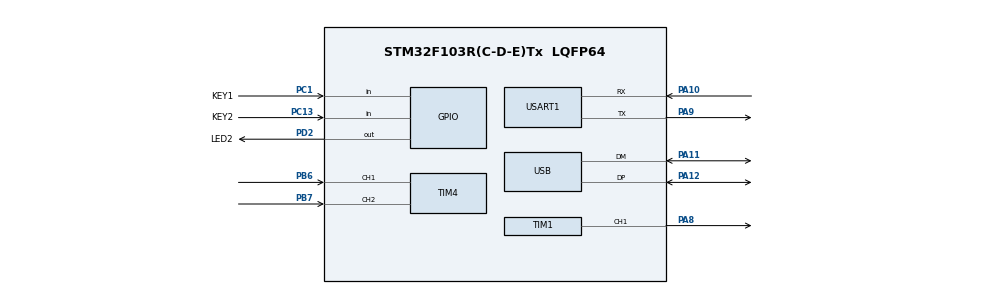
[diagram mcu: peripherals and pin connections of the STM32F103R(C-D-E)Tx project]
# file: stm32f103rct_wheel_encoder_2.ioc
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Mcu.Family=STM32F1
Mcu.Name=STM32F103R(C-D-E)Tx
Mcu.Package=LQFP64
NVIC.PriorityGroup=NVIC_PRIORITYGROUP_4
NVIC.TIM4_IRQn=true\:0\:0\:false\:false\:true\:true\:true\:true
NVIC.USART1_IRQn=true\:0\:0\:false\:false\:true\:true\:true\:true
NVIC.USB_LP_CAN1_RX0_IRQn=true\:0\:0\:false\:false\:true\:false\:true\:true
PA10.Mode=Asynchronous
PA10.Signal=USART1_RX
PA11.Mode=Device
PA11.Signal=USB_DM
PA12.Mode=Device
PA12.Signal=USB_DP
PA13.Mode=Serial_Wire
PA13.Signal=SYS_JTMS-SWDIO
PA14.Mode=Serial_Wire
PA14.Signal=SYS_JTCK-SWCLK
PA8.Signal=S_TIM1_CH1
PA9.Mode=Asynchronous
PA9.Signal=USART1_TX
PB6.Signal=S_TIM4_CH1
PB7.Signal=S_TIM4_CH2
PC1.GPIO_Label=KEY1
PC1.Signal=GPIO_Input
PC13-TAMPER-RTC.GPIO_Label=KEY2
PC13-TAMPER-RTC.Signal=GPIO_Input
PC14-OSC32_IN.Mode=LSE-External-Oscillator
PC14-OSC32_IN.Signal=RCC_OSC32_IN
PC15-OSC32_OUT.Mode=LSE-External-Oscillator
PC15-OSC32_OUT.Signal=RCC_OSC32_OUT
PD0-OSC_IN.Mode=HSE-External-Oscillator
PD0-OSC_IN.Signal=RCC_OSC_IN
PD1-OSC_OUT.Mode=HSE-External-Oscillator
PD1-OSC_OUT.Signal=RCC_OSC_OUT
PD2.GPIO_Label=LED2
PD2.Signal=GPIO_Output
ProjectManager.HeapSize=0x200
ProjectManager.StackSize=0x400
ProjectManager.TargetToolchain=STM32CubeIDE
RCC.AHBFreq_Value=72000000
RCC.APB1CLKDivider=RCC_HCLK_DIV2
RCC.APB1Freq_Value=36000000
RCC.APB1TimFreq_Value=72000000
RCC.APB2Freq_Value=72000000
RCC.APB2TimFreq_Value=72000000
RCC.HCLKFreq_Value=72000000
RCC.PLLMUL=RCC_PLL_MUL9
RCC.SYSCLKFreq_VALUE=72000000
RCC.SYSCLKSource=RCC_SYSCLKSOURCE_PLLCLK
RCC.USBFreq_Value=48000000
RCC.USBPrescaler=RCC_USBCLKSOURCE_PLL_DIV1_5
SH.S_TIM1_CH1.0=TIM1_CH1,PWM Generation1 CH1
SH.S_TIM4_CH1.0=TIM4_CH1,Encoder_Interface
SH.S_TIM4_CH2.0=TIM4_CH2,Encoder_Interface
TIM1.Channel-PWM\ Generation1\ CH1=TIM_CHANNEL_1
TIM1.Period=99
TIM1.Prescaler=72
TIM4.EncoderMode=TIM_ENCODERMODE_TI12
USART1.VirtualMode=VM_ASYNC
USB_DEVICE.APP_RX_DATA_SIZE=512
USB_DEVICE.APP_TX_DATA_SIZE=512
USB_DEVICE.CLASS_NAME_FS=CDC
USB_DEVICE.PRODUCT_STRING_CDC_FS=STM32F103 CDC
USB_DEVICE.VirtualMode=Cdc
USB_DEVICE.VirtualModeFS=Cdc_FS
VP_RTC_VS_RTC_Activate.Mode=RTC_Enabled
VP_TIM1_VS_ClockSourceINT.Mode=Internal
VP_USB_DEVICE_VS_USB_DEVICE_CDC_FS.Mode=CDC_FS
board=custom

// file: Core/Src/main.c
/* USER CODE BEGIN Header */
/**
  ******************************************************************************
  * @file           : main.c
  * @brief          : Main program body
  ******************************************************************************
  * @attention
  *
  * Copyright (c) 2023 STMicroelectronics.
  * All rights reserved.
  *
  * This software is licensed under terms that can be found in the LICENSE file
  * in the root directory of this software component.
  * If no LICENSE file comes with this software, it is provided AS-IS.
  *
  ******************************************************************************
  */
/* USER CODE END Header */
#include "main.h"
#include "usb_device.h"

RTC_HandleTypeDef hrtc;

TIM_HandleTypeDef htim1;
TIM_HandleTypeDef htim4;

UART_HandleTypeDef huart1;

void SystemClock_Config(void);
static void MX_GPIO_Init(void);
static void MX_RTC_Init(void);
static void MX_TIM4_Init(void);
static void MX_USART1_UART_Init(void);
static void MX_TIM1_Init(void);

/* USER CODE BEGIN 0 */

volatile uint32_t encoder_cnt = 0;

void HAL_TIM_PeriodElapsedCallback(TIM_HandleTypeDef *htim)
{
  encoder_cnt = __HAL_TIM_GET_COUNTER(&htim4);
}

/* USER CODE END 0 */

int main(void)
{

  /* MCU Configuration--------------------------------------------------------*/

  /* Reset of all peripherals, Initializes the Flash interface and the Systick. */
  HAL_Init();

  /* Configure the system clock */
  SystemClock_Config();

  /* Initialize all configured peripherals */
  MX_GPIO_Init();
  MX_RTC_Init();
  MX_USB_DEVICE_Init();
  MX_TIM4_Init();
  MX_USART1_UART_Init();
  MX_TIM1_Init();
  /* USER CODE BEGIN 2 */

  //HAL_TIM_Encoder_Start(&htim4, TIM_CHANNEL_1 |TIM_CHANNEL_2);
  /* USER CODE END 2 */

  /* Infinite loop */
  while (1)
  {

    /* USER CODE BEGIN 3 */
    //encoder_cnt = __HAL_TIM_GET_COUNTER(&htim4);

  }
  /* USER CODE END 3 */
}

void SystemClock_Config(void)
{
  LL_FLASH_SetLatency(LL_FLASH_LATENCY_2);
  while(LL_FLASH_GetLatency()!= LL_FLASH_LATENCY_2)
  {
  }
  LL_RCC_HSE_Enable();

   /* Wait till HSE is ready */
  while(LL_RCC_HSE_IsReady() != 1)
  {

  }
  LL_RCC_LSI_Enable();

   /* Wait till LSI is ready */
  while(LL_RCC_LSI_IsReady() != 1)
  {

  }
  LL_PWR_EnableBkUpAccess();
  if(LL_RCC_GetRTCClockSource() != LL_RCC_RTC_CLKSOURCE_LSI)
  {
    LL_RCC_ForceBackupDomainReset();
    LL_RCC_ReleaseBackupDomainReset();
    LL_RCC_SetRTCClockSource(LL_RCC_RTC_CLKSOURCE_LSI);
  }
  LL_RCC_EnableRTC();
  LL_RCC_PLL_ConfigDomain_SYS(LL_RCC_PLLSOURCE_HSE_DIV_1, LL_RCC_PLL_MUL_9);
  LL_RCC_PLL_Enable();

   /* Wait till PLL is ready */
  while(LL_RCC_PLL_IsReady() != 1)
  {

  }
  LL_RCC_SetAHBPrescaler(LL_RCC_SYSCLK_DIV_1);
  LL_RCC_SetAPB1Prescaler(LL_RCC_APB1_DIV_2);
  LL_RCC_SetAPB2Prescaler(LL_RCC_APB2_DIV_1);
  LL_RCC_SetSysClkSource(LL_RCC_SYS_CLKSOURCE_PLL);

   /* Wait till System clock is ready */
  while(LL_RCC_GetSysClkSource() != LL_RCC_SYS_CLKSOURCE_STATUS_PLL)
  {

  }
  LL_SetSystemCoreClock(72000000);

   /* Update the time base */
  if (HAL_InitTick (TICK_INT_PRIORITY) != HAL_OK)
  {
    Error_Handler();
  }
  LL_RCC_SetUSBClockSource(LL_RCC_USB_CLKSOURCE_PLL_DIV_1_5);
}

static void MX_RTC_Init(void)
{

  /** Initialize RTC Only
  */
  hrtc.Instance = RTC;
  hrtc.Init.AsynchPrediv = RTC_AUTO_1_SECOND;
  hrtc.Init.OutPut = RTC_OUTPUTSOURCE_ALARM;
  if (HAL_RTC_Init(&hrtc) != HAL_OK)
  {
    Error_Handler();
  }

}

static void MX_TIM1_Init(void)
{

  TIM_ClockConfigTypeDef sClockSourceConfig = {0};
  TIM_MasterConfigTypeDef sMasterConfig = {0};
  TIM_OC_InitTypeDef sConfigOC = {0};
  TIM_BreakDeadTimeConfigTypeDef sBreakDeadTimeConfig = {0};

  htim1.Instance = TIM1;
  htim1.Init.Prescaler = 72;
  htim1.Init.CounterMode = TIM_COUNTERMODE_UP;
  htim1.Init.Period = 99;
  htim1.Init.ClockDivision = TIM_CLOCKDIVISION_DIV1;
  htim1.Init.RepetitionCounter = 0;
  htim1.Init.AutoReloadPreload = TIM_AUTORELOAD_PRELOAD_DISABLE;
  if (HAL_TIM_Base_Init(&htim1) != HAL_OK)
  {
    Error_Handler();
  }
  sClockSourceConfig.ClockSource = TIM_CLOCKSOURCE_INTERNAL;
  if (HAL_TIM_ConfigClockSource(&htim1, &sClockSourceConfig) != HAL_OK)
  {
    Error_Handler();
  }
  if (HAL_TIM_PWM_Init(&htim1) != HAL_OK)
  {
    Error_Handler();
  }
  sMasterConfig.MasterOutputTrigger = TIM_TRGO_RESET;
  sMasterConfig.MasterSlaveMode = TIM_MASTERSLAVEMODE_DISABLE;
  if (HAL_TIMEx_MasterConfigSynchronization(&htim1, &sMasterConfig) != HAL_OK)
  {
    Error_Handler();
  }
  sConfigOC.OCMode = TIM_OCMODE_PWM1;
  sConfigOC.Pulse = 0;
  sConfigOC.OCPolarity = TIM_OCPOLARITY_HIGH;
  sConfigOC.OCNPolarity = TIM_OCNPOLARITY_HIGH;
  sConfigOC.OCFastMode = TIM_OCFAST_DISABLE;
  sConfigOC.OCIdleState = TIM_OCIDLESTATE_RESET;
  sConfigOC.OCNIdleState = TIM_OCNIDLESTATE_RESET;
  if (HAL_TIM_PWM_ConfigChannel(&htim1, &sConfigOC, TIM_CHANNEL_1) != HAL_OK)
  {
    Error_Handler();
  }
  sBreakDeadTimeConfig.OffStateRunMode = TIM_OSSR_DISABLE;
  sBreakDeadTimeConfig.OffStateIDLEMode = TIM_OSSI_DISABLE;
  sBreakDeadTimeConfig.LockLevel = TIM_LOCKLEVEL_OFF;
  sBreakDeadTimeConfig.DeadTime = 0;
  sBreakDeadTimeConfig.BreakState = TIM_BREAK_DISABLE;
  sBreakDeadTimeConfig.BreakPolarity = TIM_BREAKPOLARITY_HIGH;
  sBreakDeadTimeConfig.AutomaticOutput = TIM_AUTOMATICOUTPUT_DISABLE;
  if (HAL_TIMEx_ConfigBreakDeadTime(&htim1, &sBreakDeadTimeConfig) != HAL_OK)
  {
    Error_Handler();
  }
  HAL_TIM_MspPostInit(&htim1);

}

static void MX_TIM4_Init(void)
{

  TIM_Encoder_InitTypeDef sConfig = {0};
  TIM_MasterConfigTypeDef sMasterConfig = {0};

  htim4.Instance = TIM4;
  htim4.Init.Prescaler = 0;
  htim4.Init.CounterMode = TIM_COUNTERMODE_UP;
  htim4.Init.Period = 65535;
  htim4.Init.ClockDivision = TIM_CLOCKDIVISION_DIV1;
  htim4.Init.AutoReloadPreload = TIM_AUTORELOAD_PRELOAD_DISABLE;
  sConfig.EncoderMode = TIM_ENCODERMODE_TI12;
  sConfig.IC1Polarity = TIM_ICPOLARITY_RISING;
  sConfig.IC1Selection = TIM_ICSELECTION_DIRECTTI;
  sConfig.IC1Prescaler = TIM_ICPSC_DIV1;
  sConfig.IC1Filter = 0;
  sConfig.IC2Polarity = TIM_ICPOLARITY_RISING;
  sConfig.IC2Selection = TIM_ICSELECTION_DIRECTTI;
  sConfig.IC2Prescaler = TIM_ICPSC_DIV1;
  sConfig.IC2Filter = 0;
  if (HAL_TIM_Encoder_Init(&htim4, &sConfig) != HAL_OK)
  {
    Error_Handler();
  }
  sMasterConfig.MasterOutputTrigger = TIM_TRGO_RESET;
  sMasterConfig.MasterSlaveMode = TIM_MASTERSLAVEMODE_DISABLE;
  if (HAL_TIMEx_MasterConfigSynchronization(&htim4, &sMasterConfig) != HAL_OK)
  {
    Error_Handler();
  }
  /* USER CODE BEGIN TIM4_Init 2 */
  HAL_TIM_Encoder_Start(&htim4, TIM_CHANNEL_ALL);
  /* USER CODE END TIM4_Init 2 */

}

static void MX_USART1_UART_Init(void)
{

  huart1.Instance = USART1;
  huart1.Init.BaudRate = 115200;
  huart1.Init.WordLength = UART_WORDLENGTH_8B;
  huart1.Init.StopBits = UART_STOPBITS_1;
  huart1.Init.Parity = UART_PARITY_NONE;
  huart1.Init.Mode = UART_MODE_TX_RX;
  huart1.Init.HwFlowCtl = UART_HWCONTROL_NONE;
  huart1.Init.OverSampling = UART_OVERSAMPLING_16;
  if (HAL_UART_Init(&huart1) != HAL_OK)
  {
    Error_Handler();
  }

}

static void MX_GPIO_Init(void)
{
  GPIO_InitTypeDef GPIO_InitStruct = {0};

  /* GPIO Ports Clock Enable */
  __HAL_RCC_GPIOC_CLK_ENABLE();
  __HAL_RCC_GPIOD_CLK_ENABLE();
  __HAL_RCC_GPIOA_CLK_ENABLE();
  __HAL_RCC_GPIOB_CLK_ENABLE();

  /*Configure GPIO pin Output Level */
  HAL_GPIO_WritePin(LED2_GPIO_Port, LED2_Pin, GPIO_PIN_RESET);

  /*Configure GPIO pins : KEY2_Pin KEY1_Pin */
  GPIO_InitStruct.Pin = KEY2_Pin|KEY1_Pin;
  GPIO_InitStruct.Mode = GPIO_MODE_INPUT;
  GPIO_InitStruct.Pull = GPIO_NOPULL;
  HAL_GPIO_Init(GPIOC, &GPIO_InitStruct);

  /*Configure GPIO pin : LED2_Pin */
  GPIO_InitStruct.Pin = LED2_Pin;
  GPIO_InitStruct.Mode = GPIO_MODE_OUTPUT_PP;
  GPIO_InitStruct.Pull = GPIO_NOPULL;
  GPIO_InitStruct.Speed = GPIO_SPEED_FREQ_LOW;
  HAL_GPIO_Init(LED2_GPIO_Port, &GPIO_InitStruct);

}

void Error_Handler(void)
{
  __disable_irq();
  while (1)
  {
  }
}
